VERSION ""

NS_ :

BS_:

BU_: IC ECU
VAL_TABLE_ ecu_work_state 4 "OVERRUN" 3 "RUN" 2 "START" 1 "STOP" 0 "INIT" ;
VAL_TABLE_ throttle_position_valid 1 "Valid" 0 "Invalid" ;
VAL_TABLE_ MalfunctionIndicatorLampStatus 3 "Fast Flash" 2 "Slow Flash" 1 "ON" 0 "OFF" ;

BO_ 770 ECU_DBG_03: 8 Vector__XXX
 SG_ fuel_pulse_width : 0|16@1+ (0.0008,0) [0|0] "ms" Vector__XXX

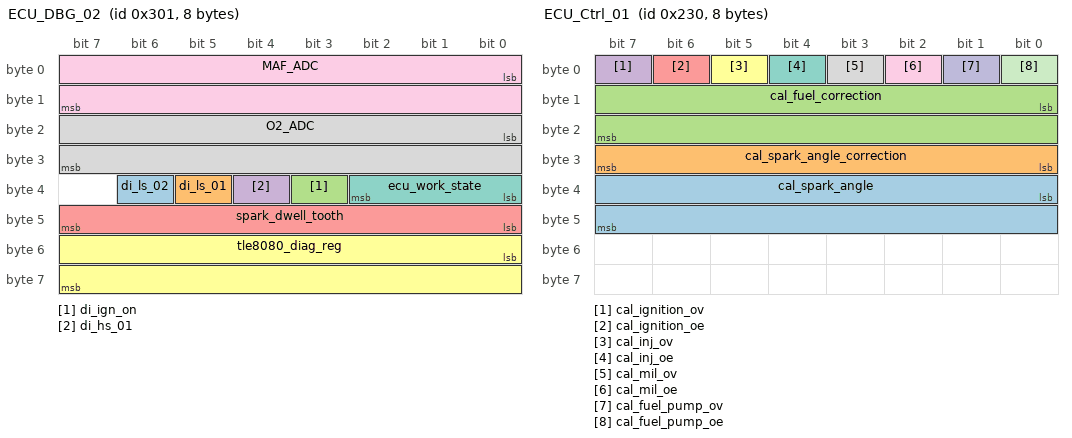
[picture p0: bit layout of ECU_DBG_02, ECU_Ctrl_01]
BO_ 769 ECU_DBG_02: 8 Vector__XXX
 SG_ di_ls_02 : 38|1@1+ (1,0) [0|0] "" Vector__XXX
 SG_ di_ls_01 : 37|1@1+ (1,0) [0|0] "" Vector__XXX
 SG_ di_ign_on : 35|1@1+ (1,0) [0|0] "" Vector__XXX
 SG_ di_hs_01 : 36|1@1+ (1,0) [0|0] "" Vector__XXX
 SG_ spark_dwell_tooth : 40|8@1+ (1,0) [0|0] "" Vector__XXX
 SG_ tle8080_diag_reg : 48|16@1+ (1,0) [0|0] "" Vector__XXX
 SG_ ecu_work_state : 32|3@1+ (1,0) [0|0] "" Vector__XXX
 SG_ O2_ADC : 16|16@1+ (1,0) [0|0] "" Vector__XXX
 SG_ MAF_ADC : 0|16@1+ (1,0) [0|0] "" Vector__XXX

BO_ 560 ECU_Ctrl_01: 8 Vector__XXX
 SG_ cal_spark_angle : 32|16@1+ (1,0) [0|0] "" Vector__XXX
 SG_ cal_spark_angle_correction : 24|8@1+ (1,-24) [-24|24] "" Vector__XXX
 SG_ cal_fuel_correction : 8|16@1+ (0.0008,-26) [-26|26.428] "" Vector__XXX
 SG_ cal_ignition_ov : 7|1@1+ (1,0) [0|0] "" Vector__XXX
 SG_ cal_ignition_oe : 6|1@1+ (1,0) [0|0] "" Vector__XXX
 SG_ cal_inj_ov : 5|1@1+ (1,0) [0|0] "" Vector__XXX
 SG_ cal_inj_oe : 4|1@1+ (1,0) [0|0] "" Vector__XXX
 SG_ cal_mil_ov : 3|1@1+ (1,0) [0|0] "" Vector__XXX
 SG_ cal_mil_oe : 2|1@1+ (1,0) [0|0] "" Vector__XXX
 SG_ cal_fuel_pump_ov : 1|1@1+ (1,0) [0|0] "" Vector__XXX
 SG_ cal_fuel_pump_oe : 0|1@1+ (1,0) [0|0] "" Vector__XXX

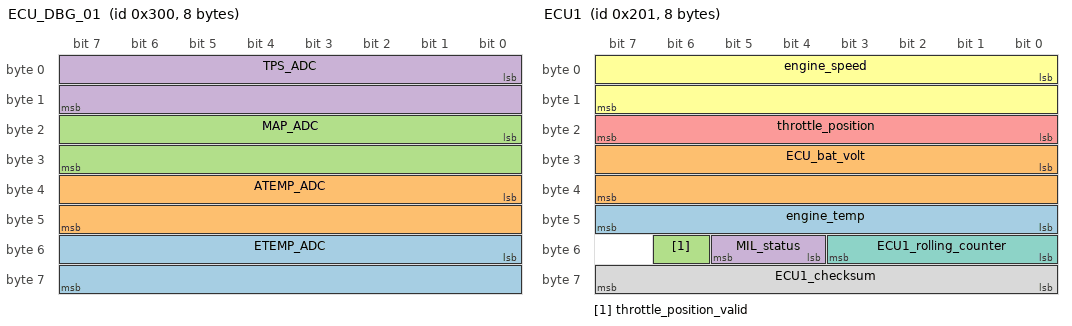
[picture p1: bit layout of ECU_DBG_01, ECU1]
BO_ 768 ECU_DBG_01: 8 ECU
 SG_ ETEMP_ADC : 48|16@1+ (1,0) [0|0] "" Vector__XXX
 SG_ ATEMP_ADC : 32|16@1+ (1,0) [0|0] "" Vector__XXX
 SG_ MAP_ADC : 16|16@1+ (1,0) [0|0] "" Vector__XXX
 SG_ TPS_ADC : 0|16@1+ (1,0) [0|0] "" Vector__XXX

BO_ 513 ECU1: 8 ECU
 SG_ engine_temp : 40|8@1+ (1,-40) [-40|210] "degC" Vector__XXX
 SG_ ECU_bat_volt : 24|16@1+ (1,0) [0|0] "mV" Vector__XXX
 SG_ throttle_position_valid : 54|1@1+ (1,0) [0|1] "" Vector__XXX
 SG_ MIL_status : 52|2@1+ (1,0) [0|0] "" Vector__XXX
 SG_ throttle_position : 16|8@1+ (0.5,0) [0|100] "%"  IC
 SG_ engine_speed : 0|16@1+ (1,0) [0|9000] "RPM"  IC
 SG_ ECU1_rolling_counter : 48|4@1+ (1,0) [0|15] ""  IC
 SG_ ECU1_checksum : 56|8@1+ (1,0) [0|255] ""  IC

BA_DEF_ SG_  "GenSigSendType" ENUM  "Cyclic","OnWrite","OnWriteWithRepetition","OnChange","OnChangeWithRepetition","IfActive","IfActiveWithRepetition","NoSigSendType";
BA_DEF_  "DBName" STRING ;
BA_DEF_ BO_  "GenMsgCycleTime" INT 0 0;
BA_DEF_ BO_  "GenMsgSendType" ENUM  "Cyclic","not_used","not_used","not_used","not_used","Cyclic","not_used","IfActive","NoMsgSendType";
BA_DEF_DEF_  "GenSigSendType" "Cyclic";
BA_DEF_DEF_  "DBName" "";
BA_DEF_DEF_  "GenMsgCycleTime" 0;
BA_DEF_DEF_  "GenMsgSendType" "NoMsgSendType";
BA_ "DBName" "Motorcycle_PCAN_Matrix";
BA_ "GenMsgSendType" BO_ 768 0;
BA_ "GenMsgCycleTime" BO_ 768 10;
VAL_ 769 ecu_work_state 4 "OVERRUN" 3 "RUN" 2 "START" 1 "STOP" 0 "INIT" ;
VAL_ 513 throttle_position_valid 1 "Valid" 0 "Invalid" ;
VAL_ 513 MIL_status 3 "Fast Flash" 2 "Slow Flash" 1 "ON" 0 "OFF" ;
